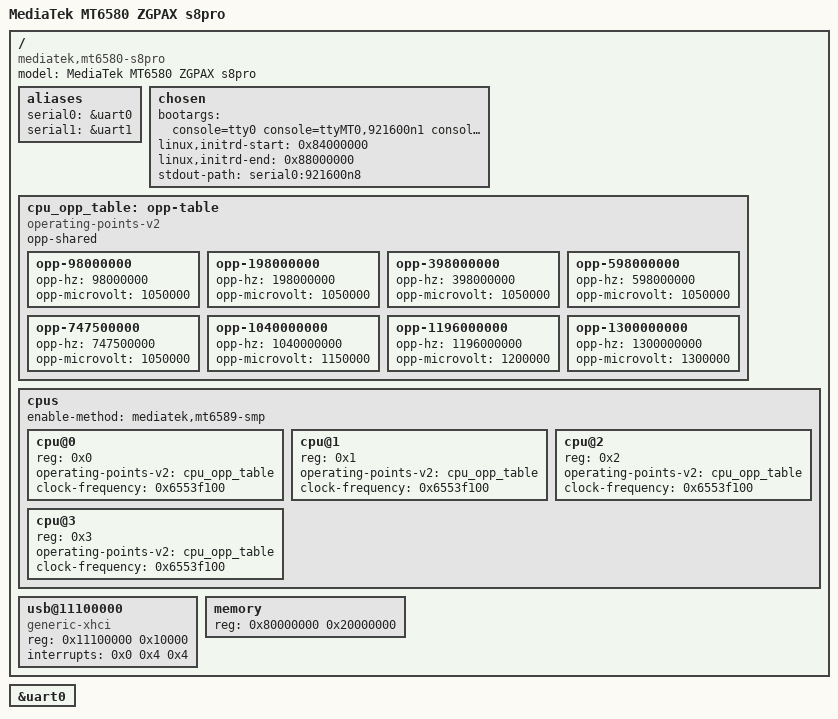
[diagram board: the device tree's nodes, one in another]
// SPDX-License-Identifier: GPL-2.0
/*
 * Copyright (c) 2015 MediaTek Inc.
 * Author: Mars.C <mars.cheng@mediatek.com>
 *
 */

/dts-v1/;
#include "mt6580.dtsi"
#include <dt-bindings/phy/phy.h>

/ {
	model = "MediaTek MT6580 ZGPAX s8pro";
	compatible = "mediatek,mt6580-s8pro", "mediatek,mt6580";

	aliases {
		serial0 = &uart0;
		serial1 = &uart1;
	};

	chosen {
        bootargs = "console=tty0 console=ttyMT0,921600n1 console=ttyS0,921600n8 initrd=0x84000000,0x04000000 loglevel=8 vram=1048576 ramoops.mem_address=0x83f10000 ramoops.mem_size=0xe0000 ramoops.console_size=0x10000 ramoops.ecc=1";
		linux,initrd-start = <0x84000000>;
		linux,initrd-end = <0x88000000>;
		stdout-path = "serial0:921600n8";
	};

	cpu_opp_table: opp-table {
		compatible = "operating-points-v2";
		opp-shared;

		opp-98000000 {
			opp-hz = /bits/ 64 <98000000>;
			opp-microvolt = <1050000>;
		};

		opp-198000000 {
			opp-hz = /bits/ 64 <198000000>;
			opp-microvolt = <1050000>;
		};

		opp-398000000 {
			opp-hz = /bits/ 64 <398000000>;
			opp-microvolt = <1050000>;
		};

		opp-598000000 {
			opp-hz = /bits/ 64 <598000000>;
			opp-microvolt = <1050000>;
		};

		opp-747500000 {
			opp-hz = /bits/ 64 <747500000>;
			opp-microvolt = <1050000>;
		};

		opp-1040000000 {
			opp-hz = /bits/ 64 <1040000000>;
			opp-microvolt = <1150000>;
		};

		opp-1196000000 {
			opp-hz = /bits/ 64 <1196000000>;
			opp-microvolt = <1200000>;
		};

		opp-1300000000 {
			opp-hz = /bits/ 64 <1300000000>;
			opp-microvolt = <1300000>;
		};
	};

    cpus {
		enable-method = "mediatek,mt6589-smp";
        cpu@0 {
            reg = <0x0>;
//			clocks = <&infracfg CLK_INFRA_CPUSEL>,
//				 <&apmixedsys CLK_APMIXED_MAINPLL>;
//			clock-names = "cpu", "intermediate";
			operating-points-v2 = <&cpu_opp_table>;
			#cooling-cells = <2>;
            clock-frequency = <0x6553f100>;
        };
        cpu@1 {
            reg = <0x1>;
//			clocks = <&infracfg CLK_INFRA_CPUSEL>,
//				 <&apmixedsys CLK_APMIXED_MAINPLL>;
//			clock-names = "cpu", "intermediate";
			operating-points-v2 = <&cpu_opp_table>;
			#cooling-cells = <2>;
            clock-frequency = <0x6553f100>;
        };
        cpu@2 {
            reg = <0x2>;
//			clocks = <&infracfg CLK_INFRA_CPUSEL>,
//				 <&apmixedsys CLK_APMIXED_MAINPLL>;
//			clock-names = "cpu", "intermediate";
			operating-points-v2 = <&cpu_opp_table>;
			#cooling-cells = <2>;
            clock-frequency = <0x6553f100>;
        };
        cpu@3 {
            reg = <0x3>;
//			clocks = <&infracfg CLK_INFRA_CPUSEL>,
//				 <&apmixedsys CLK_APMIXED_MAINPLL>;
//			clock-names = "cpu", "intermediate";
			operating-points-v2 = <&cpu_opp_table>;
			#cooling-cells = <2>;
            clock-frequency = <0x6553f100>;
        };
    };

	usb@11100000 {
		compatible = "generic-xhci";
		reg = <0x11100000 0x10000>;
            interrupts = <0x0 0x4 0x4>;
	};

/*    
	usb0: usb@11100000 {
		compatible = "mediatek,mt6580-xhci",
				"mediatek,mt8173-xhci";
		reg = <0 0x11100000 0 0x10000>,
			<0 0x11100000 0 0x10000>;
		reg-names = "mac", "ippc";
//		interrupts = <GIC_SPI 196 IRQ_TYPE_LEVEL_LOW>;
//		clocks = <&hifsys CLK_HIFSYS_USB0PHY>,
//			<&topckgen CLK_TOP_ETHIF_SEL>;
//		clock-names = "sys_ck", "ref_ck";
//		power-domains = <&scpsys MT2701_POWER_DOMAIN_HIF>;
		phys = <&u2port0 PHY_TYPE_USB2>, <&u3port0 PHY_TYPE_USB3>;
		status = "disabled";
	};

	u3phy0: usb-phy@11100000 {
		compatible = "mediatek,mt6580-u3phy",
			     "mediatek,mt2701-u3phy";
		reg = <0 0x11100000 0 0x10000>;
		#address-cells = <2>;
		#size-cells = <2>;
		ranges;
		status = "disabled";

		u2port0: usb-phy@11100800 {
			reg = <0 0x11100800 0 0x01000>;
//			clocks = <&topckgen CLK_TOP_USB_PHY48M>;
//			clock-names = "ref";
			#phy-cells = <1>;
			status = "okay";
		};

		u3port0: usb-phy@11100900 {
			reg = <0 0x11100900 0 0x10000>;
//			clocks = <&clk26m>;
//			clock-names = "ref";
			#phy-cells = <1>;
			status = "okay";
		};
	};
*/
	memory {
		device_type = "memory";
		reg = <0x80000000 0x20000000>;
	};
};

&uart0 {
	status = "okay";
};
